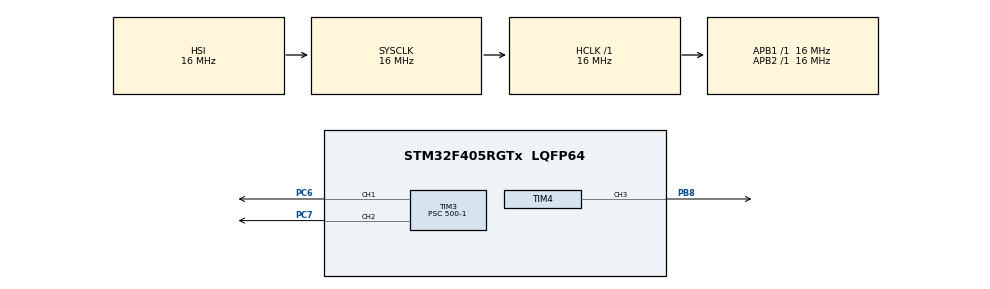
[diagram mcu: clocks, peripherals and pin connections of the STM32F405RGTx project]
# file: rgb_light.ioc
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Mcu.Family=STM32F4
Mcu.Name=STM32F405RGTx
Mcu.Package=LQFP64
NVIC.PriorityGroup=NVIC_PRIORITYGROUP_4
PB8.Signal=S_TIM4_CH3
PC6.Signal=S_TIM3_CH1
PC7.Signal=S_TIM3_CH2
ProjectManager.HeapSize=0x200
ProjectManager.StackSize=0x400
ProjectManager.TargetToolchain=MDK-ARM V5
RCC.AHBFreq_Value=16000000
RCC.APB1Freq_Value=16000000
RCC.APB2Freq_Value=16000000
RCC.CortexFreq_Value=16000000
RCC.HSE_VALUE=25000000
RCC.HSI_VALUE=16000000
RCC.LSE_VALUE=32768
RCC.SYSCLKFreq_VALUE=16000000
RCC.VCOOutputFreq_Value=192000000
SH.S_TIM3_CH1.0=TIM3_CH1,PWM Generation1 CH1
SH.S_TIM3_CH2.0=TIM3_CH2,PWM Generation2 CH2
SH.S_TIM4_CH3.0=TIM4_CH3,PWM Generation3 CH3
TIM3.Channel-PWM\ Generation1\ CH1=TIM_CHANNEL_1
TIM3.Channel-PWM\ Generation2\ CH2=TIM_CHANNEL_2
TIM3.Period=84-1
TIM3.Prescaler=500-1
TIM3.Pulse-PWM\ Generation1\ CH1=100
TIM3.Pulse-PWM\ Generation2\ CH2=100
TIM4.Channel-PWM\ Generation3\ CH3=TIM_CHANNEL_3
TIM4.Period=84-1
TIM4.Prescaler=500-1
TIM4.Pulse-PWM\ Generation3\ CH3=100
board=custom

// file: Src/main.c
/* USER CODE BEGIN Header */
/**
  ******************************************************************************
  * @file           : main.c
  * @brief          : Main program body
  ******************************************************************************
  * @attention
  *
  * <h2><center>&copy; Copyright (c) 2019 STMicroelectronics.
  * All rights reserved.</center></h2>
  *
  * This software component is licensed by ST under BSD 3-Clause license,
  * the "License"; You may not use this file except in compliance with the
  * License. You may obtain a copy of the License at:
  *                        opensource.org/licenses/BSD-3-Clause
  *
  ******************************************************************************
  */
/* USER CODE END Header */

#include "main.h"

TIM_HandleTypeDef htim3;
TIM_HandleTypeDef htim4;

void SystemClock_Config(void);
static void MX_GPIO_Init(void);
static void MX_TIM3_Init(void);
static void MX_TIM4_Init(void);

/* USER CODE BEGIN 0 */
void ImprovePwm(TIM_HandleTypeDef *htim,uint32_t chanel,uint16_t pulse_value);
/* USER CODE END 0 */

int main(void)
{
  /* USER CODE BEGIN 1 */
	uint16_t i;
  /* USER CODE END 1 */

  /* MCU Configuration--------------------------------------------------------*/

  /* Reset of all peripherals, Initializes the Flash interface and the Systick. */
  HAL_Init();

  /* Configure the system clock */
  SystemClock_Config();

  /* Initialize all configured peripherals */
  MX_GPIO_Init();
  MX_TIM3_Init();
  MX_TIM4_Init();
  /* USER CODE BEGIN 2 */
	HAL_TIMEx_PWMN_Start(&htim3,TIM_CHANNEL_1);
	HAL_TIMEx_PWMN_Start(&htim4,TIM_CHANNEL_1);
	HAL_TIMEx_PWMN_Start(&htim3,TIM_CHANNEL_2);
  /* USER CODE END 2 */

  /* Infinite loop */
  /* USER CODE BEGIN WHILE */
  while (1)
  {
		for(i=0;i<100;i++)
		{
			ImprovePwm(&htim3,TIM_CHANNEL_1,i);
		}
		for(i=0;i<100;i++)
		{
			ImprovePwm(&htim4,TIM_CHANNEL_1,i);
		}

		for(i=0;i<100;i++)
		{
			ImprovePwm(&htim3,TIM_CHANNEL_2,i);
		}
    /* USER CODE END WHILE */

  }
}

void SystemClock_Config(void)
{
  RCC_OscInitTypeDef RCC_OscInitStruct = {0};
  RCC_ClkInitTypeDef RCC_ClkInitStruct = {0};

  /** Configure the main internal regulator output voltage
  */
  __HAL_RCC_PWR_CLK_ENABLE();
  __HAL_PWR_VOLTAGESCALING_CONFIG(PWR_REGULATOR_VOLTAGE_SCALE1);
  /** Initializes the CPU, AHB and APB busses clocks
  */
  RCC_OscInitStruct.OscillatorType = RCC_OSCILLATORTYPE_HSI;
  RCC_OscInitStruct.HSIState = RCC_HSI_ON;
  RCC_OscInitStruct.HSICalibrationValue = RCC_HSICALIBRATION_DEFAULT;
  RCC_OscInitStruct.PLL.PLLState = RCC_PLL_NONE;
  if (HAL_RCC_OscConfig(&RCC_OscInitStruct) != HAL_OK)
  {
    Error_Handler();
  }
  /** Initializes the CPU, AHB and APB busses clocks
  */
  RCC_ClkInitStruct.ClockType = RCC_CLOCKTYPE_HCLK|RCC_CLOCKTYPE_SYSCLK
                              |RCC_CLOCKTYPE_PCLK1|RCC_CLOCKTYPE_PCLK2;
  RCC_ClkInitStruct.SYSCLKSource = RCC_SYSCLKSOURCE_HSI;
  RCC_ClkInitStruct.AHBCLKDivider = RCC_SYSCLK_DIV1;
  RCC_ClkInitStruct.APB1CLKDivider = RCC_HCLK_DIV1;
  RCC_ClkInitStruct.APB2CLKDivider = RCC_HCLK_DIV1;

  if (HAL_RCC_ClockConfig(&RCC_ClkInitStruct, FLASH_LATENCY_0) != HAL_OK)
  {
    Error_Handler();
  }
}

static void MX_TIM3_Init(void)
{

  TIM_MasterConfigTypeDef sMasterConfig = {0};
  TIM_OC_InitTypeDef sConfigOC = {0};

  htim3.Instance = TIM3;
  htim3.Init.Prescaler = 500-1;
  htim3.Init.CounterMode = TIM_COUNTERMODE_UP;
  htim3.Init.Period = 84-1;
  htim3.Init.ClockDivision = TIM_CLOCKDIVISION_DIV1;
  htim3.Init.AutoReloadPreload = TIM_AUTORELOAD_PRELOAD_DISABLE;
  if (HAL_TIM_PWM_Init(&htim3) != HAL_OK)
  {
    Error_Handler();
  }
  sMasterConfig.MasterOutputTrigger = TIM_TRGO_RESET;
  sMasterConfig.MasterSlaveMode = TIM_MASTERSLAVEMODE_DISABLE;
  if (HAL_TIMEx_MasterConfigSynchronization(&htim3, &sMasterConfig) != HAL_OK)
  {
    Error_Handler();
  }
  sConfigOC.OCMode = TIM_OCMODE_PWM1;
  sConfigOC.Pulse = 100;
  sConfigOC.OCPolarity = TIM_OCPOLARITY_HIGH;
  sConfigOC.OCFastMode = TIM_OCFAST_DISABLE;
  if (HAL_TIM_PWM_ConfigChannel(&htim3, &sConfigOC, TIM_CHANNEL_1) != HAL_OK)
  {
    Error_Handler();
  }
  if (HAL_TIM_PWM_ConfigChannel(&htim3, &sConfigOC, TIM_CHANNEL_2) != HAL_OK)
  {
    Error_Handler();
  }
  HAL_TIM_MspPostInit(&htim3);

}

static void MX_TIM4_Init(void)
{

  TIM_MasterConfigTypeDef sMasterConfig = {0};
  TIM_OC_InitTypeDef sConfigOC = {0};

  htim4.Instance = TIM4;
  htim4.Init.Prescaler = 500-1;
  htim4.Init.CounterMode = TIM_COUNTERMODE_UP;
  htim4.Init.Period = 84-1;
  htim4.Init.ClockDivision = TIM_CLOCKDIVISION_DIV1;
  htim4.Init.AutoReloadPreload = TIM_AUTORELOAD_PRELOAD_DISABLE;
  if (HAL_TIM_PWM_Init(&htim4) != HAL_OK)
  {
    Error_Handler();
  }
  sMasterConfig.MasterOutputTrigger = TIM_TRGO_RESET;
  sMasterConfig.MasterSlaveMode = TIM_MASTERSLAVEMODE_DISABLE;
  if (HAL_TIMEx_MasterConfigSynchronization(&htim4, &sMasterConfig) != HAL_OK)
  {
    Error_Handler();
  }
  sConfigOC.OCMode = TIM_OCMODE_PWM1;
  sConfigOC.Pulse = 100;
  sConfigOC.OCPolarity = TIM_OCPOLARITY_HIGH;
  sConfigOC.OCFastMode = TIM_OCFAST_DISABLE;
  if (HAL_TIM_PWM_ConfigChannel(&htim4, &sConfigOC, TIM_CHANNEL_3) != HAL_OK)
  {
    Error_Handler();
  }
  HAL_TIM_MspPostInit(&htim4);

}

static void MX_GPIO_Init(void)
{

  /* GPIO Ports Clock Enable */
  __HAL_RCC_GPIOC_CLK_ENABLE();
  __HAL_RCC_GPIOB_CLK_ENABLE();

}

/* USER CODE BEGIN 4 */
void ImprovePwm(TIM_HandleTypeDef *htim,uint32_t chanel,uint16_t pulse_value)
{
	TIM_OC_InitTypeDef sConfigOC = {0};

  sConfigOC.OCMode = TIM_OCMODE_PWM1;
  sConfigOC.Pulse = pulse_value;
  sConfigOC.OCPolarity = TIM_OCPOLARITY_HIGH;
  sConfigOC.OCFastMode = TIM_OCFAST_DISABLE;
  if (HAL_TIM_PWM_ConfigChannel(htim, &sConfigOC, chanel) != HAL_OK)
  {
    Error_Handler();
  }

}
/* USER CODE END 4 */

void Error_Handler(void)
{
}

/************************ (C) COPYRIGHT STMicroelectronics *****END OF FILE****/
